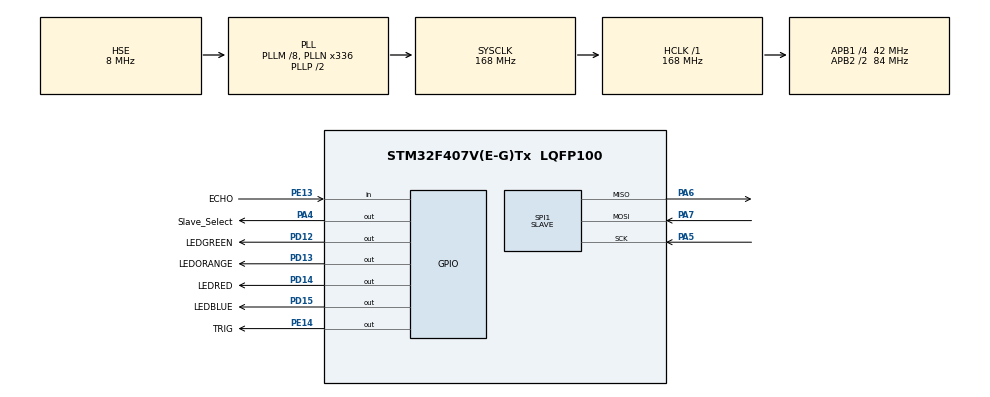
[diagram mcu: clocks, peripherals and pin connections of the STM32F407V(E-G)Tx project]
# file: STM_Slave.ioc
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Mcu.Family=STM32F4
Mcu.Name=STM32F407V(E-G)Tx
Mcu.Package=LQFP100
NVIC.PriorityGroup=NVIC_PRIORITYGROUP_0
PA4.GPIO_Label=Slave_Select
PA4.Signal=GPIO_Output
PA5.Mode=Full_Duplex_Slave
PA5.Signal=SPI1_SCK
PA6.Mode=Full_Duplex_Slave
PA6.Signal=SPI1_MISO
PA7.Mode=Full_Duplex_Slave
PA7.Signal=SPI1_MOSI
PD12.GPIO_Label=LEDGREEN
PD12.Signal=GPIO_Output
PD13.GPIO_Label=LEDORANGE
PD13.Signal=GPIO_Output
PD14.GPIO_Label=LEDRED
PD14.Signal=GPIO_Output
PD15.GPIO_Label=LEDBLUE
PD15.Signal=GPIO_Output
PE13.GPIO_Label=ECHO
PE13.Signal=GPIO_Input
PE14.GPIO_Label=TRIG
PE14.Signal=GPIO_Output
ProjectManager.HeapSize=0x200
ProjectManager.StackSize=0x400
ProjectManager.TargetToolchain=STM32CubeIDE
RCC.48MHZClocksFreq_Value=48000000
RCC.AHBFreq_Value=168000000
RCC.APB1CLKDivider=RCC_HCLK_DIV4
RCC.APB1Freq_Value=42000000
RCC.APB1TimFreq_Value=84000000
RCC.APB2CLKDivider=RCC_HCLK_DIV2
RCC.APB2Freq_Value=84000000
RCC.APB2TimFreq_Value=168000000
RCC.CortexFreq_Value=168000000
RCC.HCLKFreq_Value=168000000
RCC.HSE_VALUE=8000000
RCC.HSI_VALUE=16000000
RCC.LSE_VALUE=32768
RCC.PLLM=8
RCC.PLLN=336
RCC.PLLQ=7
RCC.PLLSourceVirtual=RCC_PLLSOURCE_HSE
RCC.SYSCLKFreq_VALUE=168000000
RCC.SYSCLKSource=RCC_SYSCLKSOURCE_PLLCLK
RCC.VCOOutputFreq_Value=336000000
SPI1.Direction=SPI_DIRECTION_2LINES
SPI1.Mode=SPI_MODE_SLAVE
SPI1.VirtualType=VM_SLAVE
board=STM32F407G-DISC1

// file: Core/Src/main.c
/* USER CODE BEGIN Header */
/**
  ******************************************************************************
  * @file           : main.c
  * @brief          : Main program body
  ******************************************************************************
  * @attention
  *
  * <h2><center>&copy; Copyright (c) 2020 STMicroelectronics.
  * All rights reserved.</center></h2>
  *
  * This software component is licensed by ST under Ultimate Liberty license
  * SLA0044, the "License"; You may not use this file except in compliance with
  * the License. You may obtain a copy of the License at:
  *                             www.st.com/SLA0044
  *
  ******************************************************************************
  */
/* USER CODE END Header */
#include "main.h"

SPI_HandleTypeDef hspi1;

/* USER CODE BEGIN PV */
#define DATA_SIZE 1
/* USER CODE END PV */

void SystemClock_Config(void);
static void MX_GPIO_Init(void);
static void MX_SPI1_Init(void);

int main(void)
{
  /* USER CODE BEGIN 1 */
	uint8_t buffer[DATA_SIZE];
	uint8_t DistanceInCM=0;
	uint8_t syson=0;
  /* USER CODE END 1 */

  /* MCU Configuration--------------------------------------------------------*/

  /* Reset of all peripherals, Initializes the Flash interface and the Systick. */
  HAL_Init();

  /* Configure the system clock */
  SystemClock_Config();

  /* Initialize all configured peripherals */
  MX_GPIO_Init();
  MX_SPI1_Init();

  /* Infinite loop */
  while (1)
  {
	  HAL_SPI_Receive(&hspi1, buffer, DATA_SIZE,HAL_MAX_DELAY);
	  //HAL_GPIO_WritePin(LED_GPIO_Port, LED_Pin, GPIO_PIN_SET);
	  syson+=buffer[0];
	  buffer[0]=0;
	  //HAL_SPI_Receive_IT(&hspi1, buffer, DATA_SIZE);
	  if(syson==1)
	  {
		  while(1){
		  DistanceInCM=DistanceCall();
		 if(DistanceInCM<=2)
		  {
			  HAL_GPIO_WritePin(LEDORANGE_GPIO_Port, LEDORANGE_Pin, GPIO_PIN_RESET);
			  HAL_GPIO_WritePin(LEDRED_GPIO_Port, LEDRED_Pin, GPIO_PIN_RESET);
			  HAL_GPIO_WritePin(LEDGREEN_GPIO_Port, LEDGREEN_Pin, GPIO_PIN_RESET);

			  HAL_GPIO_WritePin(LEDBLUE_GPIO_Port,LEDBLUE_Pin, GPIO_PIN_SET);
		  }
		  else if(DistanceInCM>2 && DistanceInCM<=4)
		  {
			  HAL_GPIO_WritePin(LEDBLUE_GPIO_Port,LEDBLUE_Pin, GPIO_PIN_RESET);
			  HAL_GPIO_WritePin(LEDORANGE_GPIO_Port, LEDORANGE_Pin, GPIO_PIN_RESET);
			  HAL_GPIO_WritePin(LEDGREEN_GPIO_Port, LEDGREEN_Pin, GPIO_PIN_RESET);
			  HAL_GPIO_WritePin(LEDRED_GPIO_Port, LEDRED_Pin, GPIO_PIN_SET);
		  }
		  else if(DistanceInCM>4 && DistanceInCM<=7)
		  {
			  HAL_GPIO_WritePin(LEDBLUE_GPIO_Port,LEDBLUE_Pin, GPIO_PIN_RESET);
			  HAL_GPIO_WritePin(LEDRED_GPIO_Port, LEDRED_Pin, GPIO_PIN_RESET);
			  HAL_GPIO_WritePin(LEDGREEN_GPIO_Port, LEDGREEN_Pin, GPIO_PIN_RESET);
			  HAL_GPIO_WritePin(LEDORANGE_GPIO_Port, LEDORANGE_Pin, GPIO_PIN_SET);
		  }
		  else if(DistanceInCM>7 && DistanceInCM<=15)
		  {
			  HAL_GPIO_WritePin(LEDBLUE_GPIO_Port,LEDBLUE_Pin, GPIO_PIN_SET);
			  HAL_GPIO_WritePin(LEDGREEN_GPIO_Port, LEDGREEN_Pin, GPIO_PIN_SET);
			  HAL_GPIO_WritePin(LEDORANGE_GPIO_Port, LEDORANGE_Pin, GPIO_PIN_SET);
			  HAL_GPIO_WritePin(LEDRED_GPIO_Port, LEDRED_Pin, GPIO_PIN_SET);
		  }
		  else
		  {
			  HAL_GPIO_WritePin(LEDBLUE_GPIO_Port,LEDBLUE_Pin, GPIO_PIN_RESET);
			  HAL_GPIO_WritePin(LEDGREEN_GPIO_Port, LEDGREEN_Pin, GPIO_PIN_RESET);
			  HAL_GPIO_WritePin(LEDORANGE_GPIO_Port, LEDORANGE_Pin, GPIO_PIN_RESET);
			  HAL_GPIO_WritePin(LEDRED_GPIO_Port, LEDRED_Pin, GPIO_PIN_RESET);
		  }
		 }
	  }
	  else if(syson==2)
	  {
		  syson=0;
	  }
  }
}

void SystemClock_Config(void)
{
  RCC_OscInitTypeDef RCC_OscInitStruct = {0};
  RCC_ClkInitTypeDef RCC_ClkInitStruct = {0};

  /** Configure the main internal regulator output voltage
  */
  __HAL_RCC_PWR_CLK_ENABLE();
  __HAL_PWR_VOLTAGESCALING_CONFIG(PWR_REGULATOR_VOLTAGE_SCALE1);
  /** Initializes the RCC Oscillators according to the specified parameters
  * in the RCC_OscInitTypeDef structure.
  */
  RCC_OscInitStruct.OscillatorType = RCC_OSCILLATORTYPE_HSE;
  RCC_OscInitStruct.HSEState = RCC_HSE_OFF;
  RCC_OscInitStruct.PLL.PLLState = RCC_PLL_ON;
  RCC_OscInitStruct.PLL.PLLSource = RCC_PLLSOURCE_HSE;
  RCC_OscInitStruct.PLL.PLLM = 8;
  RCC_OscInitStruct.PLL.PLLN = 336;
  RCC_OscInitStruct.PLL.PLLP = RCC_PLLP_DIV2;
  RCC_OscInitStruct.PLL.PLLQ = 7;
  if (HAL_RCC_OscConfig(&RCC_OscInitStruct) != HAL_OK)
  {
    Error_Handler();
  }
  /** Initializes the CPU, AHB and APB buses clocks
  */
  RCC_ClkInitStruct.ClockType = RCC_CLOCKTYPE_HCLK|RCC_CLOCKTYPE_SYSCLK
                              |RCC_CLOCKTYPE_PCLK1|RCC_CLOCKTYPE_PCLK2;
  RCC_ClkInitStruct.SYSCLKSource = RCC_SYSCLKSOURCE_PLLCLK;
  RCC_ClkInitStruct.AHBCLKDivider = RCC_SYSCLK_DIV1;
  RCC_ClkInitStruct.APB1CLKDivider = RCC_HCLK_DIV4;
  RCC_ClkInitStruct.APB2CLKDivider = RCC_HCLK_DIV2;

  if (HAL_RCC_ClockConfig(&RCC_ClkInitStruct, FLASH_LATENCY_5) != HAL_OK)
  {
    Error_Handler();
  }
}

static void MX_SPI1_Init(void)
{

  /* SPI1 parameter configuration*/
  hspi1.Instance = SPI1;
  hspi1.Init.Mode = SPI_MODE_SLAVE;
  hspi1.Init.Direction = SPI_DIRECTION_2LINES;
  hspi1.Init.DataSize = SPI_DATASIZE_8BIT;
  hspi1.Init.CLKPolarity = SPI_POLARITY_LOW;
  hspi1.Init.CLKPhase = SPI_PHASE_1EDGE;
  hspi1.Init.NSS = SPI_NSS_SOFT;
  hspi1.Init.FirstBit = SPI_FIRSTBIT_MSB;
  hspi1.Init.TIMode = SPI_TIMODE_DISABLE;
  hspi1.Init.CRCCalculation = SPI_CRCCALCULATION_DISABLE;
  hspi1.Init.CRCPolynomial = 10;
  if (HAL_SPI_Init(&hspi1) != HAL_OK)
  {
    Error_Handler();
  }

}

static void MX_GPIO_Init(void)
{
  GPIO_InitTypeDef GPIO_InitStruct = {0};

  /* GPIO Ports Clock Enable */
  __HAL_RCC_GPIOA_CLK_ENABLE();
  __HAL_RCC_GPIOE_CLK_ENABLE();
  __HAL_RCC_GPIOD_CLK_ENABLE();

  /*Configure GPIO pin Output Level */
  HAL_GPIO_WritePin(Slave_Select_GPIO_Port, Slave_Select_Pin, GPIO_PIN_RESET);

  /*Configure GPIO pin Output Level */
  HAL_GPIO_WritePin(TRIG_GPIO_Port, TRIG_Pin, GPIO_PIN_RESET);

  /*Configure GPIO pin Output Level */
  HAL_GPIO_WritePin(GPIOD, LEDGREEN_Pin|LEDORANGE_Pin|LEDRED_Pin|LEDBLUE_Pin, GPIO_PIN_RESET);

  /*Configure GPIO pin : Slave_Select_Pin */
  GPIO_InitStruct.Pin = Slave_Select_Pin;
  GPIO_InitStruct.Mode = GPIO_MODE_OUTPUT_PP;
  GPIO_InitStruct.Pull = GPIO_NOPULL;
  GPIO_InitStruct.Speed = GPIO_SPEED_FREQ_LOW;
  HAL_GPIO_Init(Slave_Select_GPIO_Port, &GPIO_InitStruct);

  /*Configure GPIO pin : ECHO_Pin */
  GPIO_InitStruct.Pin = ECHO_Pin;
  GPIO_InitStruct.Mode = GPIO_MODE_INPUT;
  GPIO_InitStruct.Pull = GPIO_NOPULL;
  HAL_GPIO_Init(ECHO_GPIO_Port, &GPIO_InitStruct);

  /*Configure GPIO pin : TRIG_Pin */
  GPIO_InitStruct.Pin = TRIG_Pin;
  GPIO_InitStruct.Mode = GPIO_MODE_OUTPUT_PP;
  GPIO_InitStruct.Pull = GPIO_NOPULL;
  GPIO_InitStruct.Speed = GPIO_SPEED_FREQ_LOW;
  HAL_GPIO_Init(TRIG_GPIO_Port, &GPIO_InitStruct);

  /*Configure GPIO pins : LEDGREEN_Pin LEDORANGE_Pin LEDRED_Pin LEDBLUE_Pin */
  GPIO_InitStruct.Pin = LEDGREEN_Pin|LEDORANGE_Pin|LEDRED_Pin|LEDBLUE_Pin;
  GPIO_InitStruct.Mode = GPIO_MODE_OUTPUT_PP;
  GPIO_InitStruct.Pull = GPIO_NOPULL;
  GPIO_InitStruct.Speed = GPIO_SPEED_FREQ_LOW;
  HAL_GPIO_Init(GPIOD, &GPIO_InitStruct);

}

void Error_Handler(void)
{
}

/************************ (C) COPYRIGHT STMicroelectronics *****END OF FILE****/
